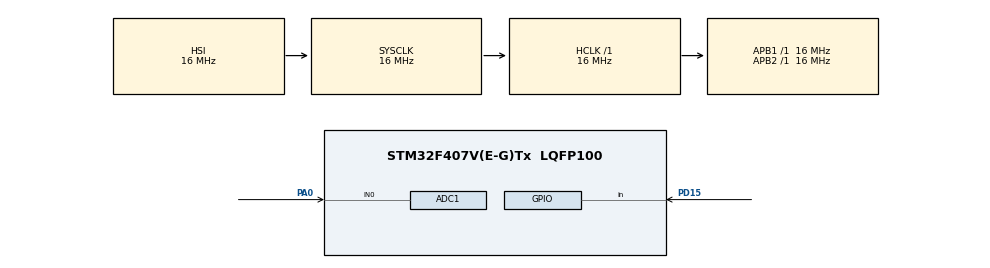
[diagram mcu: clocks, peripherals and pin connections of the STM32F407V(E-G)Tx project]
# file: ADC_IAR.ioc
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ADC1.Channel-0\#ChannelRegularConversion=ADC_CHANNEL_0
ADC1.ClockPrescaler=ADC_CLOCK_SYNC_PCLK_DIV8
ADC1.ContinuousConvMode=ENABLE
ADC1.NbrOfConversionFlag=1
ADC1.Rank-0\#ChannelRegularConversion=1
ADC1.Resolution=ADC_RESOLUTION_8B
ADC1.SamplingTime-0\#ChannelRegularConversion=ADC_SAMPLETIME_480CYCLES
ADC1.master=1
Mcu.Family=STM32F4
Mcu.Name=STM32F407V(E-G)Tx
Mcu.Package=LQFP100
NVIC.PriorityGroup=NVIC_PRIORITYGROUP_4
PA0-WKUP.Signal=ADCx_IN0
PD15.Signal=GPIO_Input
ProjectManager.HeapSize=0x200
ProjectManager.StackSize=0x400
ProjectManager.TargetToolchain=EWARM
RCC.AHBFreq_Value=16000000
RCC.APB1Freq_Value=16000000
RCC.APB2Freq_Value=16000000
RCC.CortexFreq_Value=16000000
RCC.HSE_VALUE=25000000
RCC.HSI_VALUE=16000000
RCC.LSE_VALUE=32768
RCC.SYSCLKFreq_VALUE=16000000
RCC.VCOOutputFreq_Value=192000000
SH.ADCx_IN0.0=ADC1_IN0,IN0
board=custom

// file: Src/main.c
/**
  ******************************************************************************
  * @file           : main.c
  * @brief          : Main program body
  ******************************************************************************
  ** This notice applies to any and all portions of this file
  * that are not between comment pairs USER CODE BEGIN and
  * USER CODE END. Other portions of this file, whether
  * inserted by the user or by software development tools
  * are owned by their respective copyright owners.
  *
  * COPYRIGHT(c) 2018 STMicroelectronics
  *
  * Redistribution and use in source and binary forms, with or without modification,
  * are permitted provided that the following conditions are met:
  *   1. Redistributions of source code must retain the above copyright notice,
  *      this list of conditions and the following disclaimer.
  *   2. Redistributions in binary form must reproduce the above copyright notice,
  *      this list of conditions and the following disclaimer in the documentation
  *      and/or other materials provided with the distribution.
  *   3. Neither the name of STMicroelectronics nor the names of its contributors
  *      may be used to endorse or promote products derived from this software
  *      without specific prior written permission.
  *
  * THIS SOFTWARE IS PROVIDED BY THE COPYRIGHT HOLDERS AND CONTRIBUTORS "AS IS"
  * AND ANY EXPRESS OR IMPLIED WARRANTIES, INCLUDING, BUT NOT LIMITED TO, THE
  * IMPLIED WARRANTIES OF MERCHANTABILITY AND FITNESS FOR A PARTICULAR PURPOSE ARE
  * DISCLAIMED. IN NO EVENT SHALL THE COPYRIGHT HOLDER OR CONTRIBUTORS BE LIABLE
  * FOR ANY DIRECT, INDIRECT, INCIDENTAL, SPECIAL, EXEMPLARY, OR CONSEQUENTIAL
  * DAMAGES (INCLUDING, BUT NOT LIMITED TO, PROCUREMENT OF SUBSTITUTE GOODS OR
  * SERVICES; LOSS OF USE, DATA, OR PROFITS; OR BUSINESS INTERRUPTION) HOWEVER
  * CAUSED AND ON ANY THEORY OF LIABILITY, WHETHER IN CONTRACT, STRICT LIABILITY,
  * OR TORT (INCLUDING NEGLIGENCE OR OTHERWISE) ARISING IN ANY WAY OUT OF THE USE
  * OF THIS SOFTWARE, EVEN IF ADVISED OF THE POSSIBILITY OF SUCH DAMAGE.
  *
  ******************************************************************************
  */
#include "main.h"
#include "stm32f4xx_hal.h"

ADC_HandleTypeDef hadc1;

/* USER CODE BEGIN PV */
/* Private variables ---------------------------------------------------------*/
uint32_t adcVal;
/* USER CODE END PV */

void SystemClock_Config(void);
static void MX_GPIO_Init(void);
static void MX_ADC1_Init(void);

/* USER CODE BEGIN PFP */
/* Private function prototypes -----------------------------------------------*/

/* USER CODE END PFP */

int main(void)
{

  /* MCU Configuration----------------------------------------------------------*/

  /* Reset of all peripherals, Initializes the Flash interface and the Systick. */
  HAL_Init();

  /* Configure the system clock */
  SystemClock_Config();

  /* Initialize all configured peripherals */
  MX_GPIO_Init();
  MX_ADC1_Init();
  HAL_ADC_Init(&hadc1);

  /* Infinite loop */
  while (1)
  {
  adcVal = HAL_ADC_GetValue(&hadc1);
  }

}

void SystemClock_Config(void)
{

  RCC_OscInitTypeDef RCC_OscInitStruct;
  RCC_ClkInitTypeDef RCC_ClkInitStruct;

    /**Configure the main internal regulator output voltage
    */
  __HAL_RCC_PWR_CLK_ENABLE();

  __HAL_PWR_VOLTAGESCALING_CONFIG(PWR_REGULATOR_VOLTAGE_SCALE1);

    /**Initializes the CPU, AHB and APB busses clocks
    */
  RCC_OscInitStruct.OscillatorType = RCC_OSCILLATORTYPE_HSI;
  RCC_OscInitStruct.HSIState = RCC_HSI_ON;
  RCC_OscInitStruct.HSICalibrationValue = 16;
  RCC_OscInitStruct.PLL.PLLState = RCC_PLL_NONE;
  if (HAL_RCC_OscConfig(&RCC_OscInitStruct) != HAL_OK)
  {
    _Error_Handler(__FILE__, __LINE__);
  }

    /**Initializes the CPU, AHB and APB busses clocks
    */
  RCC_ClkInitStruct.ClockType = RCC_CLOCKTYPE_HCLK|RCC_CLOCKTYPE_SYSCLK
                              |RCC_CLOCKTYPE_PCLK1|RCC_CLOCKTYPE_PCLK2;
  RCC_ClkInitStruct.SYSCLKSource = RCC_SYSCLKSOURCE_HSI;
  RCC_ClkInitStruct.AHBCLKDivider = RCC_SYSCLK_DIV1;
  RCC_ClkInitStruct.APB1CLKDivider = RCC_HCLK_DIV1;
  RCC_ClkInitStruct.APB2CLKDivider = RCC_HCLK_DIV1;

  if (HAL_RCC_ClockConfig(&RCC_ClkInitStruct, FLASH_LATENCY_0) != HAL_OK)
  {
    _Error_Handler(__FILE__, __LINE__);
  }

    /**Configure the Systick interrupt time
    */
  HAL_SYSTICK_Config(HAL_RCC_GetHCLKFreq()/1000);

    /**Configure the Systick
    */
  HAL_SYSTICK_CLKSourceConfig(SYSTICK_CLKSOURCE_HCLK);

  /* SysTick_IRQn interrupt configuration */
  HAL_NVIC_SetPriority(SysTick_IRQn, 0, 0);
}

/* ADC1 init function */
static void MX_ADC1_Init(void)
{

  ADC_ChannelConfTypeDef sConfig;

    /**Configure the global features of the ADC (Clock, Resolution, Data Alignment and number of conversion)
    */
  hadc1.Instance = ADC1;
  hadc1.Init.ClockPrescaler = ADC_CLOCK_SYNC_PCLK_DIV8;
  hadc1.Init.Resolution = ADC_RESOLUTION_8B;
  hadc1.Init.ScanConvMode = DISABLE;
  hadc1.Init.ContinuousConvMode = ENABLE;
  hadc1.Init.DiscontinuousConvMode = DISABLE;
  hadc1.Init.ExternalTrigConvEdge = ADC_EXTERNALTRIGCONVEDGE_NONE;
  hadc1.Init.ExternalTrigConv = ADC_SOFTWARE_START;
  hadc1.Init.DataAlign = ADC_DATAALIGN_RIGHT;
  hadc1.Init.NbrOfConversion = 1;
  hadc1.Init.DMAContinuousRequests = DISABLE;
  hadc1.Init.EOCSelection = ADC_EOC_SINGLE_CONV;
  if (HAL_ADC_Init(&hadc1) != HAL_OK)
  {
    _Error_Handler(__FILE__, __LINE__);
  }

    /**Configure for the selected ADC regular channel its corresponding rank in the sequencer and its sample time.
    */
  sConfig.Channel = ADC_CHANNEL_0;
  sConfig.Rank = 1;
  sConfig.SamplingTime = ADC_SAMPLETIME_480CYCLES;
  if (HAL_ADC_ConfigChannel(&hadc1, &sConfig) != HAL_OK)
  {
    _Error_Handler(__FILE__, __LINE__);
  }

}

/** Configure pins as
        * Analog
        * Input
        * Output
        * EVENT_OUT
        * EXTI
*/
static void MX_GPIO_Init(void)
{

  GPIO_InitTypeDef GPIO_InitStruct;

  /* GPIO Ports Clock Enable */
  __HAL_RCC_GPIOA_CLK_ENABLE();
  __HAL_RCC_GPIOD_CLK_ENABLE();

  /*Configure GPIO pin : PD15 */
  GPIO_InitStruct.Pin = GPIO_PIN_15;
  GPIO_InitStruct.Mode = GPIO_MODE_INPUT;
  GPIO_InitStruct.Pull = GPIO_NOPULL;
  HAL_GPIO_Init(GPIOD, &GPIO_InitStruct);

}

void _Error_Handler(char *file, int line)
{
  while(1)
  {
  }
}

/************************ (C) COPYRIGHT STMicroelectronics *****END OF FILE****/
